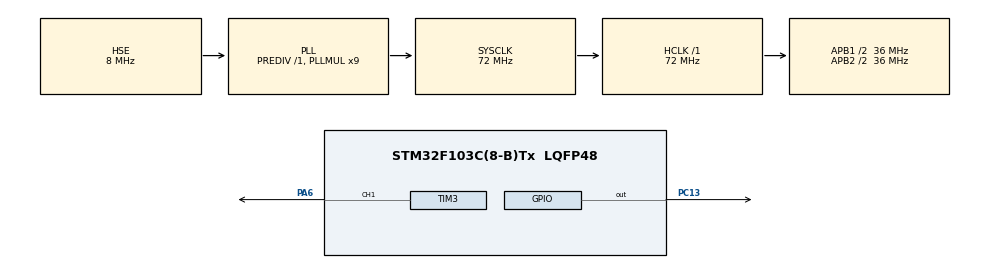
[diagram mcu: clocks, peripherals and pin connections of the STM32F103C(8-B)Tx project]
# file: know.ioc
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Dma.Request0=TIM3_CH1/TRIG
Dma.TIM3_CH1/TRIG.0.Direction=DMA_MEMORY_TO_PERIPH
Dma.TIM3_CH1/TRIG.0.Instance=DMA1_Channel6
Dma.TIM3_CH1/TRIG.0.MemDataAlignment=DMA_MDATAALIGN_HALFWORD
Dma.TIM3_CH1/TRIG.0.MemInc=DMA_MINC_ENABLE
Dma.TIM3_CH1/TRIG.0.Mode=DMA_NORMAL
Dma.TIM3_CH1/TRIG.0.PeriphDataAlignment=DMA_PDATAALIGN_HALFWORD
Dma.TIM3_CH1/TRIG.0.PeriphInc=DMA_PINC_DISABLE
Dma.TIM3_CH1/TRIG.0.Priority=DMA_PRIORITY_LOW
Mcu.Family=STM32F1
Mcu.Name=STM32F103C(8-B)Tx
Mcu.Package=LQFP48
NVIC.DMA1_Channel6_IRQn=true\:0\:0\:false\:false\:true\:false\:true\:true
NVIC.PriorityGroup=NVIC_PRIORITYGROUP_4
NVIC.TIM3_IRQn=true\:0\:0\:false\:false\:true\:true\:true\:true
PA13.Mode=Serial_Wire
PA13.Signal=SYS_JTMS-SWDIO
PA14.Mode=Serial_Wire
PA14.Signal=SYS_JTCK-SWCLK
PA6.Signal=S_TIM3_CH1
PC13-TAMPER-RTC.Signal=GPIO_Output
PD0-OSC_IN.Mode=HSE-External-Oscillator
PD0-OSC_IN.Signal=RCC_OSC_IN
PD1-OSC_OUT.Mode=HSE-External-Oscillator
PD1-OSC_OUT.Signal=RCC_OSC_OUT
ProjectManager.HeapSize=0x200
ProjectManager.StackSize=0x400
ProjectManager.TargetToolchain=STM32CubeIDE
RCC.AHBFreq_Value=72000000
RCC.APB1CLKDivider=RCC_HCLK_DIV2
RCC.APB1Freq_Value=36000000
RCC.APB1TimFreq_Value=72000000
RCC.APB2CLKDivider=RCC_HCLK_DIV2
RCC.APB2Freq_Value=36000000
RCC.APB2TimFreq_Value=72000000
RCC.HCLKFreq_Value=72000000
RCC.PLLMUL=RCC_PLL_MUL9
RCC.PLLSourceVirtual=RCC_PLLSOURCE_HSE
RCC.SYSCLKFreq_VALUE=72000000
RCC.SYSCLKSource=RCC_SYSCLKSOURCE_PLLCLK
RCC.USBFreq_Value=72000000
SH.S_TIM3_CH1.0=TIM3_CH1,PWM Generation1 CH1
TIM3.AutoReloadPreload=TIM_AUTORELOAD_PRELOAD_ENABLE
TIM3.Channel-PWM\ Generation1\ CH1=TIM_CHANNEL_1
TIM3.Period=72
TIM3.Prescaler=0
board=custom

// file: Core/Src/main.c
/* USER CODE BEGIN Header */
/**
  ******************************************************************************
  * @file           : main.c
  * @brief          : Main program body
  ******************************************************************************
  * @attention
  *
  * Copyright (c) 2024 STMicroelectronics.
  * All rights reserved.
  *
  * This software is licensed under terms that can be found in the LICENSE file
  * in the root directory of this software component.
  * If no LICENSE file comes with this software, it is provided AS-IS.
  *
  ******************************************************************************
  */
/* USER CODE END Header */
#include "main.h"

/* USER CODE BEGIN Includes */

#define MAX_LED 8
#define MAX_BRIGHTNESS 45
#define USE_BRIGHTNESS 0
#define PI 3.14159265
#define LED_OFF 0
#define LED_ON 255

typedef struct {
	int green;
	int red;
	int blue;
}st_GRB_LedColor;

uint8_t LED_Data[MAX_LED][4];
uint8_t LED_Mod[MAX_LED][4];
uint8_t datasentflag = 0;
uint16_t pwmData[(24 * MAX_LED) + 50];

void Set_LED(int LEDnum, st_GRB_LedColor color);
void Reset_LED (int LEDnum);
void Set_Brightness(int brightness);
void WS2812_Send(void);

/* USER CODE END Includes */

TIM_HandleTypeDef htim3;
DMA_HandleTypeDef hdma_tim3_ch1_trig;

void SystemClock_Config(void);
static void MX_GPIO_Init(void);
static void MX_DMA_Init(void);
static void MX_TIM3_Init(void);

int main(void)
{

  /* MCU Configuration--------------------------------------------------------*/

  /* Reset of all peripherals, Initializes the Flash interface and the Systick. */
  HAL_Init();

  /* Configure the system clock */
  SystemClock_Config();

  /* Initialize all configured peripherals */
  MX_GPIO_Init();
  MX_DMA_Init();
  MX_TIM3_Init();
  /* USER CODE BEGIN 2 */

  st_GRB_LedColor white = {255, 255, 255};

  /* USER CODE END 2 */

  /* Infinite loop */
  while (1)
  {

    /* USER CODE BEGIN 3 */
	  for(int i=0 ; i<8 ; i++) {
		  Set_LED(i, white);
		  HAL_Delay(300);
		  Reset_LED(i);
	  }

	  for(int i=7 ; i>=0 ; i--) {
		  Set_LED(i, white);
		  HAL_Delay(300);
		  Reset_LED(i);
	  }

  }
  /* USER CODE END 3 */
}

void SystemClock_Config(void)
{
  RCC_OscInitTypeDef RCC_OscInitStruct = {0};
  RCC_ClkInitTypeDef RCC_ClkInitStruct = {0};

  /** Initializes the RCC Oscillators according to the specified parameters
  * in the RCC_OscInitTypeDef structure.
  */
  RCC_OscInitStruct.OscillatorType = RCC_OSCILLATORTYPE_HSE;
  RCC_OscInitStruct.HSEState = RCC_HSE_ON;
  RCC_OscInitStruct.HSEPredivValue = RCC_HSE_PREDIV_DIV1;
  RCC_OscInitStruct.HSIState = RCC_HSI_ON;
  RCC_OscInitStruct.PLL.PLLState = RCC_PLL_ON;
  RCC_OscInitStruct.PLL.PLLSource = RCC_PLLSOURCE_HSE;
  RCC_OscInitStruct.PLL.PLLMUL = RCC_PLL_MUL9;
  if (HAL_RCC_OscConfig(&RCC_OscInitStruct) != HAL_OK)
  {
    Error_Handler();
  }

  /** Initializes the CPU, AHB and APB buses clocks
  */
  RCC_ClkInitStruct.ClockType = RCC_CLOCKTYPE_HCLK|RCC_CLOCKTYPE_SYSCLK
                              |RCC_CLOCKTYPE_PCLK1|RCC_CLOCKTYPE_PCLK2;
  RCC_ClkInitStruct.SYSCLKSource = RCC_SYSCLKSOURCE_PLLCLK;
  RCC_ClkInitStruct.AHBCLKDivider = RCC_SYSCLK_DIV1;
  RCC_ClkInitStruct.APB1CLKDivider = RCC_HCLK_DIV2;
  RCC_ClkInitStruct.APB2CLKDivider = RCC_HCLK_DIV2;

  if (HAL_RCC_ClockConfig(&RCC_ClkInitStruct, FLASH_LATENCY_2) != HAL_OK)
  {
    Error_Handler();
  }
}

static void MX_TIM3_Init(void)
{

  TIM_MasterConfigTypeDef sMasterConfig = {0};
  TIM_OC_InitTypeDef sConfigOC = {0};

  htim3.Instance = TIM3;
  htim3.Init.Prescaler = 0;
  htim3.Init.CounterMode = TIM_COUNTERMODE_UP;
  htim3.Init.Period = 72;
  htim3.Init.ClockDivision = TIM_CLOCKDIVISION_DIV1;
  htim3.Init.AutoReloadPreload = TIM_AUTORELOAD_PRELOAD_ENABLE;
  if (HAL_TIM_PWM_Init(&htim3) != HAL_OK)
  {
    Error_Handler();
  }
  sMasterConfig.MasterOutputTrigger = TIM_TRGO_RESET;
  sMasterConfig.MasterSlaveMode = TIM_MASTERSLAVEMODE_DISABLE;
  if (HAL_TIMEx_MasterConfigSynchronization(&htim3, &sMasterConfig) != HAL_OK)
  {
    Error_Handler();
  }
  sConfigOC.OCMode = TIM_OCMODE_PWM1;
  sConfigOC.Pulse = 0;
  sConfigOC.OCPolarity = TIM_OCPOLARITY_HIGH;
  sConfigOC.OCFastMode = TIM_OCFAST_DISABLE;
  if (HAL_TIM_PWM_ConfigChannel(&htim3, &sConfigOC, TIM_CHANNEL_1) != HAL_OK)
  {
    Error_Handler();
  }
  HAL_TIM_MspPostInit(&htim3);

}

static void MX_DMA_Init(void)
{

  /* DMA controller clock enable */
  __HAL_RCC_DMA1_CLK_ENABLE();

  /* DMA interrupt init */
  /* DMA1_Channel6_IRQn interrupt configuration */
  HAL_NVIC_SetPriority(DMA1_Channel6_IRQn, 0, 0);
  HAL_NVIC_EnableIRQ(DMA1_Channel6_IRQn);

}

static void MX_GPIO_Init(void)
{
  GPIO_InitTypeDef GPIO_InitStruct = {0};

  /* GPIO Ports Clock Enable */
  __HAL_RCC_GPIOC_CLK_ENABLE();
  __HAL_RCC_GPIOD_CLK_ENABLE();
  __HAL_RCC_GPIOA_CLK_ENABLE();

  /*Configure GPIO pin Output Level */
  HAL_GPIO_WritePin(GPIOC, GPIO_PIN_13, GPIO_PIN_RESET);

  /*Configure GPIO pin : PC13 */
  GPIO_InitStruct.Pin = GPIO_PIN_13;
  GPIO_InitStruct.Mode = GPIO_MODE_OUTPUT_PP;
  GPIO_InitStruct.Pull = GPIO_NOPULL;
  GPIO_InitStruct.Speed = GPIO_SPEED_FREQ_LOW;
  HAL_GPIO_Init(GPIOC, &GPIO_InitStruct);

}

/* USER CODE BEGIN 4 */

// WS2812B Data transmission function

void HAL_TIM_PWM_PulseFinishedCallback(TIM_HandleTypeDef *htim)
{
	HAL_TIM_PWM_Stop_DMA(&htim3, TIM_CHANNEL_1);
	datasentflag=1;
}

void Reset_LED (int LEDnum)
{
	LED_Data[LEDnum][0] = LEDnum;
	LED_Data[LEDnum][1] = 0;
	LED_Data[LEDnum][2] = 0;
	LED_Data[LEDnum][3] = 0;
	WS2812_Send();
}

void Set_LED (int LEDnum, st_GRB_LedColor color)
{
	LED_Data[LEDnum][0] = LEDnum;
	LED_Data[LEDnum][1] = color.green;
	LED_Data[LEDnum][2] = color.red;
	LED_Data[LEDnum][3] = color.blue;
	WS2812_Send();
}

void Set_Brightness (int brightness)  // 0-45
{
#if USE_BRIGHTNESS

	if (brightness > 45) brightness = 45;
	for (int i=0; i<MAX_LED; i++)
	{
		LED_Mod[i][0] = LED_Data[i][0];
		for (int j=1; j<4; j++)
		{
			float angle = 90-brightness;  // in degrees
			angle = angle*PI / 180;  // in rad
			LED_Mod[i][j] = (LED_Data[i][j])/(tan(angle));
		}
	}

#endif

}

void WS2812_Send (void)
{
	uint32_t indx=0;
	uint32_t color;

	for (int i= 0; i<MAX_LED; i++)
	{
#if USE_BRIGHTNESS
		color = ((LED_Mod[i][1]<<16) | (LED_Mod[i][2]<<8) | (LED_Mod[i][3]));
#else
		color = ((LED_Data[i][1]<<16) | (LED_Data[i][2]<<8) | (LED_Data[i][3]));
#endif

		for (int i=23; i>=0; i--)
		{
			if (color&(1<<i))
			{
				pwmData[indx] = 60;  // 2/3 of 90
			}

			else pwmData[indx] = 30;  // 1/3 of 90

			indx++;
		}

	}

	for (int i=0; i<50; i++)
	{
		pwmData[indx] = 0;
		indx++;
	}

	HAL_TIM_PWM_Start_DMA(&htim3, TIM_CHANNEL_1, (uint32_t *)pwmData, indx);
	while (!datasentflag){};
	datasentflag = 0;
}

//void HAL_TIM_PWM_PulseFinishedCallback(TIM_HandleTypeDef *htim){
//	HAL_TIM_PWM_Stop_DMA(&htim3, TIM_CHANNEL_1);
//	htim3.Instance->CCR1 = 0;
//}

/* USER CODE END 4 */

void Error_Handler(void)
{
  __disable_irq();
  while (1)
  {
  }
}
